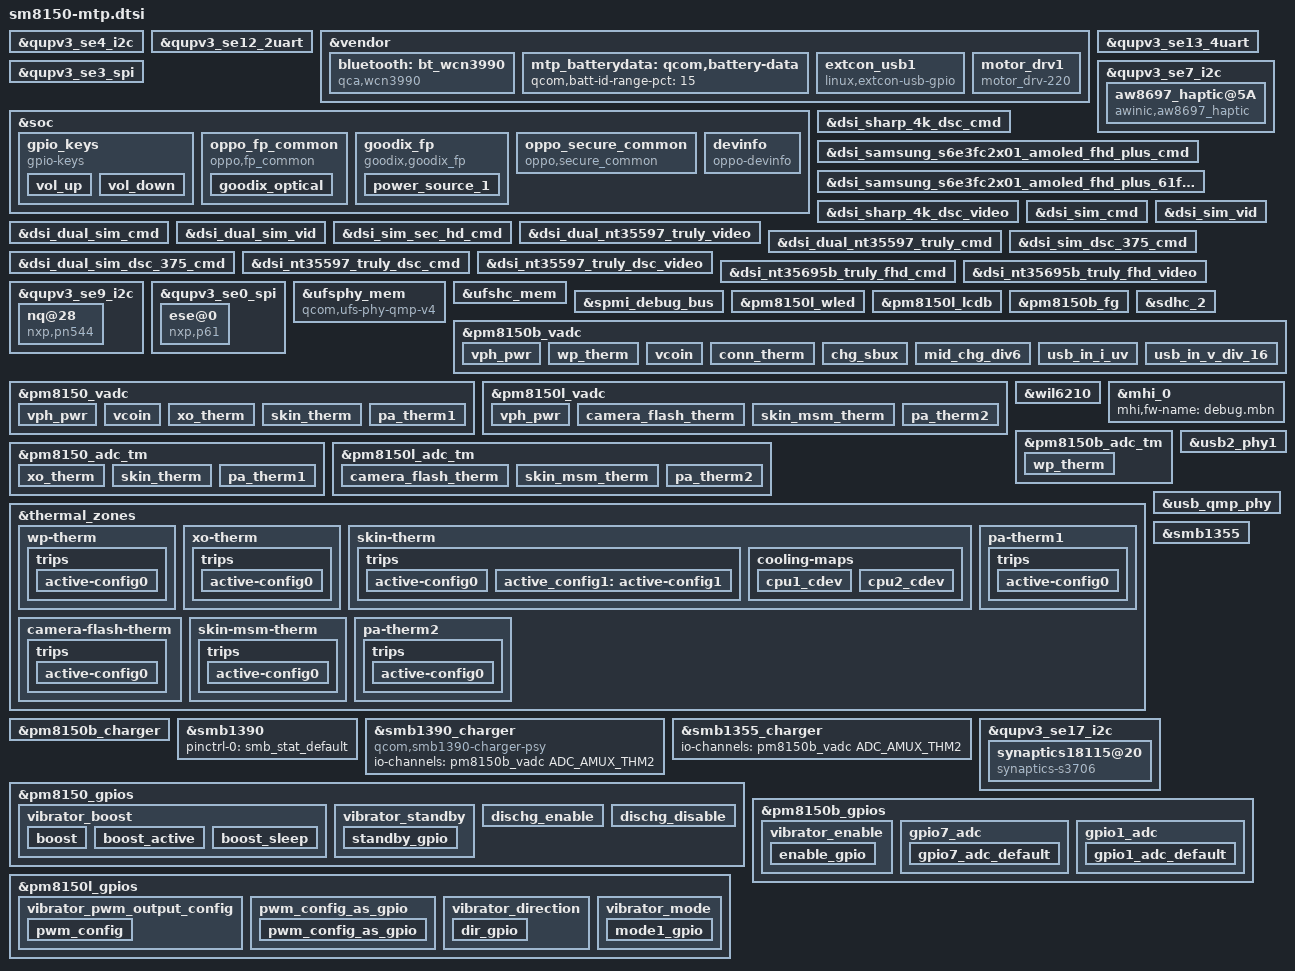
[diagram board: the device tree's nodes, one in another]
/* Copyright (c) 2017-2019, The Linux Foundation. All rights reserved.
 *
 * This program is free software; you can redistribute it and/or modify
 * it under the terms of the GNU General Public License version 2 and
 * only version 2 as published by the Free Software Foundation.
 *
 * This program is distributed in the hope that it will be useful,
 * but WITHOUT ANY WARRANTY; without even the implied warranty of
 * MERCHANTABILITY or FITNESS FOR A PARTICULAR PURPOSE.  See the
 * GNU General Public License for more details.
 */

#include <dt-bindings/gpio/gpio.h>
#include <dt-bindings/input/input.h>

#include "sm8150-pmic-overlay.dtsi"
#include "sm8150-sde-display.dtsi"
#include "sm8150-camera-sensor-mtp.dtsi"
#include "sm8150-thermal-overlay.dtsi"

&qupv3_se4_i2c {
#address-cells = <1>;
#size-cells = <0>;

#include "smb1390.dtsi"
#include "smb1355.dtsi"
};

&qupv3_se12_2uart {
	status = "ok";
};

&vendor {
	bluetooth: bt_wcn3990 {
		compatible = "qca,wcn3990";
		qca,bt-vdd-core-supply = <&pm8150_l7>;
		qca,bt-vdd-pa-supply = <&pm8150l_l2>;
		qca,bt-vdd-ldo-supply = <&pm8150l_l11>;

		qca,bt-vdd-core-voltage-level = <1800000 1800000>;
		qca,bt-vdd-pa-voltage-level = <1304000 1304000>;
		qca,bt-vdd-ldo-voltage-level = <3312000 3312000>;

		qca,bt-vdd-core-current-level = <0>; /* LPM/PFM */
		qca,bt-vdd-pa-current-level = <0>; /* LPM/PFM */
		qca,bt-vdd-ldo-current-level = <0>; /* LPM/PFM */
	};

	mtp_batterydata: qcom,battery-data {
		qcom,batt-id-range-pct = <15>;
		#include "fg-gen4-batterydata-alium-3600mah.dtsi"
	};

	extcon_usb1: extcon_usb1 {
		compatible = "linux,extcon-usb-gpio";
		//modify by cong.dai@psw.bsp.tp 2019/02/27, modified for motor
		//vbus-gpio = <&pm8150_gpios 10 GPIO_ACTIVE_HIGH>;
		/*#endif*/
                /*#ifdef VENDOR_EDIT*/
                //modify by Long.Liu 20190101, for fingerprint power gpio
		//id-gpio = <&tlmm 101 GPIO_ACTIVE_HIGH>;
                /*#endif*/
		//#ifdef VENDOR_EDIT /* tongfeng.Huang@BSP.CHG.Basic, 2018/01/08,  Add for charging chgID */
		//vbus-out-gpio = <&pm8150_gpios 9 GPIO_ACTIVE_HIGH>;
		//#endif

		pinctrl-names = "default";
		/*#ifdef VENDOR_EDIT*/
		//modify by Long.Liu 20190101, for fingerprint power gpio
		//pinctrl-0 = <&usb2_vbus_det_default
		//	     &usb2_id_det_default
		//	     &usb2_vbus_boost_default>;
		/*#endif*/

	};
};

&qupv3_se13_4uart {
	status = "ok";
};

&qupv3_se3_spi {
	status = "ok";
};

&qupv3_se4_i2c {
	status = "ok";
};


//#ifdef VENDOR_EDIT//Fanhong.Kong@ProDrv.CHG,add 2018/10/25 for vib aw8697
&qupv3_se7_i2c  {
    status = "okay";
	/* AWINIC AW8697 Haptic */
	aw8697_haptic@5A {
		compatible = "awinic,aw8697_haptic";
		reg = <0x5A>;
		reset-gpio = <&tlmm 116 0>;
		irq-gpio = <&tlmm 24 0>;
		status = "okay";

		pinctrl-names = "default";
		pinctrl-0 = <&aw_irq_gpio_default>;
	};
	/* AWINIC AW8697 Haptic End */
};
//#endif

&soc {
	gpio_keys {
		compatible = "gpio-keys";
		label = "gpio-keys";

		pinctrl-names = "default";
		/*ifdef VENDOR_EDIT*/
		//Added by wanghao@Bsp.Group.Tp for volkey,2018-11-01
		pinctrl-0 = <&key_vol_up_default &key_vol_down_default>;
		//#endif

		vol_up {
			label = "volume_up";
			gpios = <&pm8150_gpios 6 GPIO_ACTIVE_LOW>;
			linux,input-type = <1>;
			linux,code = <KEY_VOLUMEUP>;
			gpio-key,wakeup;
			debounce-interval = <15>;
			linux,can-disable;
		};

		/*ifdef VENDOR_EDIT*/
		//Added by Tong.han@Bsp.Group.Tp for device-info,2015-4-13
		vol_down {
			label = "volume_down";
			gpios = <&pm8150_gpios 7 GPIO_ACTIVE_LOW>;
			linux,input-type = <1>;
			linux,code = <KEY_VOLUMEDOWN>;
			gpio-key,wakeup;
			debounce-interval = <15>;
			linux,can-disable;
		};
		/*endif*/
	};
//#ifdef VENDOR_EDIT
//delete because this GPIO used for motor
//	qcom,qbt1000 {
//		compatible = "qcom,qbt1000";
//		clock-names = "core", "iface";
//		clock-frequency = <25000000>;
//		qcom,ipc-gpio = <&tlmm 118 0>;
//		pinctrl-names = "default";
//		pinctrl-0 = <&key_home_default>;
//		qcom,finger-detect-gpio = <&pm8150_gpios 1 0>;
//	};
//#endif

	/* #ifdef VENDOR_EDIT */
	/*Long.Liu@Bsp.Fingerprint.Basic 2018-11-27 add for fingerprint */
	oppo_fp_common {
	        compatible = "oppo,fp_common";
                oppo,fp_gpio = <130>;
                pinctrl-names = "default";
                pinctrl-0 = <&gpio_id2_default>;
                goodix_optical {
                        oppo,fp-id = <1>; /* fp id mapping table */
                        vendor-chip = <11>; /* please refer to the struct fp_vendor_t in oppo_fp_commmon.n */
                        eng-menu = "-1,-1"; /* represents SNR, inclination test item in engineer menu, and 0/1 means off/on */
                        chip-name = "G_OPTICAL_G2";  /* /proc/fp_id, will be displayed in engineer menu  */
		};
	};

	/*#ifdef VENDOR_EDIT Long.Liu@Bsp.Fingerprint.Basic 2018-11-27 add for goodix TEE */
	goodix_fp {
	        status = "ok";
	        compatible = "goodix,goodix_fp";
	        interrupt-parent = <&tlmm>;
                interrupts = <118 0>;
	        power-mode = <2> ; /*please refer to the struct fp_power_mode_t in oppo_fp_commmon.h ,0: power mode not set, 1: ldo power, 2: gpio power, 3: auto power */
	        goodix,gpio_irq = <&tlmm 118 0x1>;
	        goodix,gpio_reset = <&tlmm 131 0x0>;
	        goodix,goodix_pwr = <&tlmm 101 0x0>;
	        //ldo5-supply = <&pm660l_l5>;  // pm660l_l5 for goodix_fp
	        pinctrl-names = "default";
	        pinctrl-0 = <&gpio_goodix_irq_default>;
                power-num = <1>;
                power_source_1 {
                        power-mode = <2>;
                        power-name = "goodix,goodix_pwr";
                        delay-time = <0>;
                };
	};
	//#endif /*VENDOR_EDIT*/

	/* #ifdef VENDOR_EDIT */
	/* Long.Liu@BSP.Fingerprint.Secure 2018/12/29, add for oppo secure common */
	oppo_secure_common {
		compatible = "oppo,secure_common";
	};
	/* #endif VENDOR_EDIT */

	/*ifdef VENDOR_EDIT*/
	//Added by Tong.han@Bsp.Group.Tp for device-info,2015-4-13
	devinfo {
		compatible = "oppo-devinfo";
		Hw,sub_hwid_1 = <&pm8150b_gpios 8 0x00>;
		Hw,sub_hwid_2 = <&pm8150b_gpios 2 0x00>;
		pinctrl-names = "hw_sub1_active","hw_sub1_sleep","hw_sub2_active","hw_sub2_sleep";
		pinctrl-0 = <&hw_sub1_pullup>;
		pinctrl-1 = <&hw_sub1_pulldown>;
		pinctrl-2 = <&hw_sub2_pullup>;
		pinctrl-3 = <&hw_sub2_pulldown>;
	};
	/*endif*/
};

&dsi_sharp_4k_dsc_cmd {
	qcom,panel-supply-entries = <&dsi_panel_pwr_supply>;
	qcom,mdss-dsi-bl-pmic-control-type = "bl_ctrl_wled";
	qcom,mdss-dsi-bl-min-level = <1>;
	qcom,mdss-dsi-bl-max-level = <4095>;
	qcom,mdss-dsi-mode-sel-gpio-state = "dual_port";
	qcom,panel-mode-gpio = <&tlmm 7 0>;
	qcom,platform-te-gpio = <&tlmm 8 0>;
	qcom,platform-reset-gpio = <&tlmm 6 0>;
};

//#ifdef VENDOR_EDIT
/*
 * Gou shengjun@PSW.MM.Display.LCD.Stability, 2018/06/11,
 * modify for 18115 samsung amoled
 */
&dsi_samsung_s6e3fc2x01_amoled_fhd_plus_cmd {
	qcom,panel-supply-entries = <&dsi_panel_pwr_supply>;
	qcom,mdss-dsi-bl-pmic-control-type = "bl_ctrl_dcs";
	qcom,mdss-dsi-bl-min-level = <1>;
	qcom,mdss-dsi-bl-max-level = <1023>;
	qcom,platform-te-gpio = <&tlmm 8 0>;
	qcom,platform-reset-gpio = <&tlmm 6 0>;
};

&dsi_samsung_s6e3fc2x01_amoled_fhd_plus_61fps_cmd {
	qcom,panel-supply-entries = <&dsi_panel_pwr_supply>;
	qcom,mdss-dsi-bl-pmic-control-type = "bl_ctrl_dcs";
	qcom,mdss-dsi-bl-min-level = <1>;
	qcom,mdss-dsi-bl-max-level = <1023>;
	qcom,platform-te-gpio = <&tlmm 8 0>;
	qcom,platform-reset-gpio = <&tlmm 6 0>;
};
//#endif /*VENDOR_EDIT*/

&dsi_sharp_4k_dsc_video {
	qcom,panel-supply-entries = <&dsi_panel_pwr_supply>;
	qcom,mdss-dsi-bl-pmic-control-type = "bl_ctrl_wled";
	qcom,mdss-dsi-bl-min-level = <1>;
	qcom,mdss-dsi-bl-max-level = <4095>;
	qcom,mdss-dsi-mode-sel-gpio-state = "dual_port";
	qcom,panel-mode-gpio = <&tlmm 7 0>;
	qcom,platform-te-gpio = <&tlmm 8 0>;
	qcom,platform-reset-gpio = <&tlmm 6 0>;
};

&dsi_sim_cmd {
	qcom,panel-supply-entries = <&dsi_panel_pwr_supply>;
	qcom,mdss-dsi-bl-pmic-control-type = "bl_ctrl_dcs";
	qcom,platform-reset-gpio = <&tlmm 6 0>;
};

&dsi_sim_vid {
	qcom,panel-supply-entries = <&dsi_panel_pwr_supply>;
	qcom,mdss-dsi-bl-pmic-control-type = "bl_ctrl_dcs";
	qcom,platform-reset-gpio = <&tlmm 6 0>;
};

&dsi_dual_sim_cmd {
	qcom,panel-supply-entries = <&dsi_panel_pwr_supply>;
	qcom,mdss-dsi-bl-pmic-control-type = "bl_ctrl_dcs";
	qcom,platform-reset-gpio = <&tlmm 6 0>;
};

&dsi_dual_sim_vid {
	qcom,panel-supply-entries = <&dsi_panel_pwr_supply>;
	qcom,mdss-dsi-bl-pmic-control-type = "bl_ctrl_dcs";
	qcom,platform-reset-gpio = <&tlmm 6 0>;
};

&dsi_sim_sec_hd_cmd {
	qcom,panel-supply-entries = <&dsi_panel_pwr_supply>;
	qcom,panel-sec-supply-entries = <&dsi_panel_pwr_supply_vdd_no_labibb>;
	qcom,mdss-dsi-bl-pmic-control-type = "bl_ctrl_wled";
	qcom,mdss-dsi-bl-min-level = <1>;
	qcom,mdss-dsi-bl-max-level = <4095>;
	qcom,mdss-dsi-mode-sel-gpio-state = "single_port";
	qcom,panel-mode-gpio = <&tlmm 7 0>;
	qcom,platform-reset-gpio = <&tlmm 6 0>;
	qcom,panel-sec-mode-gpio = <&tlmm 77 0>;
	qcom,platform-sec-reset-gpio = <&tlmm 66 0>;
};

&dsi_dual_nt35597_truly_video {
	qcom,panel-supply-entries = <&dsi_panel_pwr_supply>;
	qcom,mdss-dsi-bl-pmic-control-type = "bl_ctrl_wled";
	qcom,mdss-dsi-bl-min-level = <1>;
	qcom,mdss-dsi-bl-max-level = <4095>;
	qcom,mdss-dsi-mode-sel-gpio-state = "dual_port";
	qcom,panel-mode-gpio = <&tlmm 7 0>;
	qcom,platform-te-gpio = <&tlmm 8 0>;
	qcom,platform-reset-gpio = <&tlmm 6 0>;
};

&dsi_dual_nt35597_truly_cmd {
	qcom,panel-supply-entries = <&dsi_panel_pwr_supply>;
	qcom,mdss-dsi-bl-pmic-control-type = "bl_ctrl_wled";
	qcom,mdss-dsi-bl-min-level = <1>;
	qcom,mdss-dsi-bl-max-level = <4095>;
	qcom,mdss-dsi-mode-sel-gpio-state = "dual_port";
	qcom,panel-mode-gpio = <&tlmm 7 0>;
	qcom,platform-te-gpio = <&tlmm 8 0>;
	qcom,platform-reset-gpio = <&tlmm 6 0>;
};

&dsi_sim_dsc_375_cmd {
	qcom,panel-supply-entries = <&dsi_panel_pwr_supply>;
	qcom,mdss-dsi-bl-pmic-control-type = "bl_ctrl_dcs";
	qcom,platform-reset-gpio = <&tlmm 6 0>;
};

&dsi_dual_sim_dsc_375_cmd {
	qcom,panel-supply-entries = <&dsi_panel_pwr_supply>;
	qcom,mdss-dsi-bl-pmic-control-type = "bl_ctrl_dcs";
	qcom,platform-reset-gpio = <&tlmm 6 0>;
};

&dsi_nt35597_truly_dsc_cmd {
	qcom,panel-supply-entries = <&dsi_panel_pwr_supply>;
	qcom,mdss-dsi-bl-pmic-control-type = "bl_ctrl_wled";
	qcom,mdss-dsi-bl-min-level = <1>;
	qcom,mdss-dsi-bl-max-level = <4095>;
	qcom,mdss-dsi-mode-sel-gpio-state = "single_port";
	qcom,panel-mode-gpio = <&tlmm 7 0>;
	qcom,platform-te-gpio = <&tlmm 8 0>;
	qcom,platform-reset-gpio = <&tlmm 6 0>;
};

&dsi_nt35597_truly_dsc_video {
	qcom,panel-supply-entries = <&dsi_panel_pwr_supply>;
	qcom,mdss-dsi-bl-pmic-control-type = "bl_ctrl_wled";
	qcom,mdss-dsi-bl-min-level = <1>;
	qcom,mdss-dsi-bl-max-level = <4095>;
	qcom,mdss-dsi-mode-sel-gpio-state = "single_port";
	qcom,panel-mode-gpio = <&tlmm 7 0>;
	qcom,platform-te-gpio = <&tlmm 8 0>;
	qcom,platform-reset-gpio = <&tlmm 6 0>;
};

&dsi_nt35695b_truly_fhd_cmd {
	qcom,panel-supply-entries = <&dsi_panel_pwr_supply>;
	qcom,mdss-dsi-bl-pmic-control-type = "bl_ctrl_wled";
	qcom,mdss-dsi-bl-min-level = <1>;
	qcom,mdss-dsi-bl-max-level = <4095>;
	qcom,mdss-dsi-mode-sel-gpio-state = "single_port";
	qcom,panel-mode-gpio = <&tlmm 7 0>;
	qcom,platform-te-gpio = <&tlmm 8 0>;
	qcom,platform-reset-gpio = <&tlmm 6 0>;
};

&dsi_nt35695b_truly_fhd_video {
	qcom,panel-supply-entries = <&dsi_panel_pwr_supply>;
	qcom,mdss-dsi-bl-pmic-control-type = "bl_ctrl_wled";
	qcom,mdss-dsi-bl-min-level = <1>;
	qcom,mdss-dsi-bl-max-level = <4095>;
	qcom,mdss-dsi-mode-sel-gpio-state = "single_port";
	qcom,panel-mode-gpio = <&tlmm 7 0>;
	qcom,platform-te-gpio = <&tlmm 8 0>;
	qcom,platform-reset-gpio = <&tlmm 6 0>;
};

//#ifndef VENDOR_EDIT
//Weiwei.Deng@CN.NFC.Basic.Hardware.1746553, 2018/12/20,
//Modify for dtsi for NXP NFC
/*&qupv3_se9_i2c {
	status = "ok";

	#address-cells = <1>;
	#size-cells = <0>;

	nq@28 {
		compatible = "qcom,nq-nci";
		reg = <0x28>;
		qcom,nq-irq = <&tlmm 47 0x00>;
		qcom,nq-ven = <&tlmm 41 0x00>;
		qcom,nq-firm = <&tlmm 48 0x00>;
		qcom,nq-clkreq = <&tlmm 113 0x00>;
		qcom,nq-esepwr = <&tlmm 42 0x00>;
		interrupt-parent = <&tlmm>;
		interrupts = <47 0>;
		interrupt-names = "nfc_irq";
		pinctrl-names = "nfc_active", "nfc_suspend";
		pinctrl-0 = <&nfc_int_active &nfc_enable_active
					&nfc_clk_req_active>;
		pinctrl-1 = <&nfc_int_suspend &nfc_enable_suspend
					&nfc_clk_req_suspend>;
	};
};
*/
//#else /* VENDOR_EDIT */
&qupv3_se9_i2c {
	status = "ok";
	nq@28 {
		compatible = "nxp,pn544";
		reg = <0x28>;
		nxp,pn544-irq = <&tlmm 47 0x00>;
		nxp,pn544-ven = <&tlmm 41 0x00>;
		nxp,pn544-fw-dwnld = <&tlmm 48 0x00>;
		nxp,pn544-clk-gpio = <&tlmm 113 0x00>;
		nxp,pn544-ese-pwr = <&tlmm 49 0x00>;
		interrupt-parent = <&tlmm>;
		qcom,clk-src = "BBCLK3";
		interrupts = <47 0>;
		interrupt-names = "nfc_irq";
		pinctrl-names = "nfc_active", "nfc_suspend";
		pinctrl-0 = <&nfc_int_active &nfc_enable_active
					&nfc_clk_req_active>;
		pinctrl-1 = <&nfc_int_suspend &nfc_enable_suspend
					&nfc_clk_req_suspend>;
	};
};

&qupv3_se0_spi {
    status = "ok";

    ese@0 {
        compatible = "nxp,p61";
        reg = <0>;
        spi-max-frequency = <8000000>;
    };
};
//#endif /* VENDOR_EDIT */
&ufsphy_mem {
	compatible = "qcom,ufs-phy-qmp-v4";

	vdda-phy-supply = <&pm8150_l5>;
	vdda-phy-always-on;
	vdda-pll-supply = <&pm8150l_l3>;
	vdda-phy-max-microamp = <90200>;
	vdda-pll-max-microamp = <19000>;

	status = "ok";
};

&ufshc_mem {
	vdd-hba-supply = <&ufs_phy_gdsc>;
	vdd-hba-fixed-regulator;
	vcc-supply = <&pm8150_l10>;
	vcc-voltage-level = <2504000 2950000>;
	vcc-low-voltage-sup;
	vccq-supply = <&pm8150_l9>;
	vccq2-supply = <&pm8150_s4>;
	vcc-max-microamp = <750000>;
	vccq-max-microamp = <700000>;
	vccq2-max-microamp = <750000>;

	qcom,vddp-ref-clk-supply = <&pm8150_l9>;
	qcom,vddp-ref-clk-max-microamp = <100>;

	status = "ok";
};

&spmi_debug_bus {
	status = "ok";
};

&pm8150l_wled {
	qcom,string-cfg= <7>;
	qcom,leds-per-string = <6>;
	status = "ok";
};

&pm8150l_lcdb {
	status = "ok";
};

&pm8150b_fg {
	qcom,battery-data = <&mtp_batterydata>;
	qcom,hold-soc-while-full;
	qcom,linearize-soc;
	qcom,five-pin-battery;
	qcom,cl-wt-enable;
	/* ESR fast calibration */
	qcom,fg-esr-timer-chg-fast = <0 7>;
	qcom,fg-esr-timer-dischg-fast = <0 7>;
	qcom,fg-esr-timer-chg-slow = <0 96>;
	qcom,fg-esr-timer-dischg-slow = <0 96>;
	qcom,fg-esr-cal-soc-thresh = <26 230>;
	qcom,fg-esr-cal-temp-thresh = <10 40>;
};

&sdhc_2 {
	vdd-supply = <&pm8150l_l9>;
	qcom,vdd-voltage-level = <2950000 2960000>;
	qcom,vdd-current-level = <200 800000>;

	vdd-io-supply = <&pm8150l_l6>;
	qcom,vdd-io-voltage-level = <1808000 2960000>;
	qcom,vdd-io-current-level = <200 22000>;

	pinctrl-names = "active", "sleep";
	pinctrl-0 = <&sdc2_clk_on  &sdc2_cmd_on &sdc2_data_on &storage_cd>;
	pinctrl-1 = <&sdc2_clk_off &sdc2_cmd_off &sdc2_data_off &storage_cd>;
//#ifndef VENDOR_EDIT
//yh@PSW.BSP.Storage.Sdcard, 2018-11-012, Add for SD card detect
	//cd-gpios = <&tlmm 96 GPIO_ACTIVE_LOW>;
//#else
	cd-gpios = <&tlmm 96 GPIO_ACTIVE_HIGH>;
//#endif

	status = "ok";
};

&pm8150b_vadc {
	vph_pwr {
		reg = <ADC_VPH_PWR>;
		label = "vph_pwr";
		qcom,pre-scaling = <1 3>;
	};

	wp_therm {
		reg = <ADC_AMUX_THM1_PU2>;
		label = "wp_therm";
		qcom,ratiometric;
		qcom,hw-settle-time = <200>;
		qcom,pre-scaling = <1 1>;
	};

	vcoin {
		reg = <ADC_VCOIN>;
		label = "vcoin";
		qcom,pre-scaling = <1 3>;
	};

	conn_therm {
		reg = <ADC_AMUX_THM3_PU2>;
		label = "conn_therm";
		qcom,ratiometric;
		qcom,hw-settle-time = <200>;
		qcom,pre-scaling = <1 1>;
	};

	chg_sbux {
		reg = <ADC_SBUx>;
		label = "chg_sbux";
		qcom,pre-scaling = <1 3>;
	};

	mid_chg_div6 {
		reg = <ADC_MID_CHG_DIV6>;
		label = "chg_mid";
		qcom,pre-scaling = <1 6>;
	};

	usb_in_i_uv {
		reg = <ADC_USB_IN_I>;
		label = "usb_in_i_uv";
		qcom,pre-scaling = <1 1>;
	};

	usb_in_v_div_16 {
		reg = <ADC_USB_IN_V_16>;
		label = "usb_in_v_div_16";
		qcom,pre-scaling = <1 16>;
	};
};

&pm8150_vadc {
	vph_pwr {
		reg = <ADC_VPH_PWR>;
		label = "vph_pwr";
		qcom,pre-scaling = <1 3>;
	};

	vcoin {
		reg = <ADC_VCOIN>;
		label = "vcoin";
		qcom,pre-scaling = <1 3>;
	};

	xo_therm {
		reg = <ADC_XO_THERM_PU2>;
		label = "xo_therm";
		qcom,ratiometric;
		qcom,hw-settle-time = <200>;
		qcom,pre-scaling = <1 1>;
	};

	skin_therm {
		reg = <ADC_AMUX_THM1_PU2>;
		label = "skin_therm";
		qcom,ratiometric;
		qcom,hw-settle-time = <200>;
		qcom,pre-scaling = <1 1>;
	};

	pa_therm1 {
		reg = <ADC_AMUX_THM2_PU2>;
		label = "pa_therm1";
		qcom,ratiometric;
		qcom,hw-settle-time = <200>;
		qcom,pre-scaling = <1 1>;
	};
};

&pm8150l_vadc {
	vph_pwr {
		reg = <ADC_VPH_PWR>;
		label = "vph_pwr";
		qcom,pre-scaling = <1 3>;
	};

	camera_flash_therm {
		reg = <ADC_AMUX_THM1_PU2>;
		label = "camera_flash_therm";
		qcom,ratiometric;
		qcom,hw-settle-time = <200>;
		qcom,pre-scaling = <1 1>;
	};

	skin_msm_therm {
		reg = <ADC_AMUX_THM2_PU2>;
		label = "skin_msm_therm";
		qcom,ratiometric;
		qcom,hw-settle-time = <200>;
		qcom,pre-scaling = <1 1>;
	};

	pa_therm2 {
		reg = <ADC_AMUX_THM3_PU2>;
		label = "pa_therm2";
		qcom,ratiometric;
		qcom,hw-settle-time = <200>;
		qcom,pre-scaling = <1 1>;
	};
};

&wil6210 {
	status = "ok";
};

&mhi_0 {
	mhi,fw-name = "debug.mbn";
};

&pm8150b_adc_tm {
	wp_therm {
		reg = <ADC_AMUX_THM1_PU2>;
		qcom,ratiometric;
		qcom,hw-settle-time = <200>;
	};
};

&pm8150_adc_tm {
	xo_therm {
		reg = <ADC_XO_THERM_PU2>;
		qcom,ratiometric;
		qcom,hw-settle-time = <200>;
	};

	skin_therm {
		reg = <ADC_AMUX_THM1_PU2>;
		qcom,ratiometric;
		qcom,hw-settle-time = <200>;
	};

	pa_therm1 {
		reg = <ADC_AMUX_THM2_PU2>;
		qcom,ratiometric;
		qcom,hw-settle-time = <200>;
	};
};

&pm8150l_adc_tm {
	camera_flash_therm {
		reg = <ADC_AMUX_THM1_PU2>;
		qcom,ratiometric;
		qcom,hw-settle-time = <200>;
	};

	skin_msm_therm {
		reg = <ADC_AMUX_THM2_PU2>;
		qcom,ratiometric;
		qcom,hw-settle-time = <200>;
	};

	pa_therm2 {
		reg = <ADC_AMUX_THM3_PU2>;
		qcom,ratiometric;
		qcom,hw-settle-time = <200>;
	};
};

&thermal_zones {
	wp-therm {
		polling-delay-passive = <0>;
		polling-delay = <0>;
		thermal-governor = "user_space";
		thermal-sensors = <&pm8150b_adc_tm ADC_AMUX_THM1_PU2>;
		wake-capable-sensor;
		trips {
			active-config0 {
				temperature = <125000>;
				hysteresis = <1000>;
				type = "passive";
			};
		};
	};

	xo-therm {
		polling-delay-passive = <0>;
		polling-delay = <0>;
		thermal-governor = "user_space";
		thermal-sensors = <&pm8150_adc_tm ADC_XO_THERM_PU2>;
		wake-capable-sensor;
		trips {
			active-config0 {
				temperature = <125000>;
				hysteresis = <1000>;
				type = "passive";
			};
		};
	};

	skin-therm {
		polling-delay-passive = <50>;
		polling-delay = <200>;
		thermal-governor = "step_wise";
		thermal-sensors = <&pm8150_adc_tm ADC_AMUX_THM1_PU2>;
		/* #ifdef VENDOR_EDIT */
		temp-track;
		/* #endif */
		wake-capable-sensor;
		trips {
			active-config0 {
				temperature = <125000>;
				hysteresis = <1000>;
				type = "passive";
			};
			active_config1: active-config1 {
				temperature = <45000>;
				hysteresis = <1000>;
				type = "passive";
			};
		};
		cooling-maps {
			cpu1_cdev {
				trip = <&active_config1>;
				cooling-device = <&CPU4 THERMAL_NO_LIMIT 12>;
			};
			cpu2_cdev {
				trip = <&active_config1>;
				cooling-device = <&CPU7 THERMAL_NO_LIMIT 15>;
			};
		};
	};

	pa-therm1 {
		polling-delay-passive = <0>;
		polling-delay = <0>;
		thermal-governor = "user_space";
		thermal-sensors = <&pm8150_adc_tm ADC_AMUX_THM2_PU2>;
		wake-capable-sensor;
		trips {
			active-config0 {
				temperature = <125000>;
				hysteresis = <1000>;
				type = "passive";
			};
		};
	};

	camera-flash-therm {
		polling-delay-passive = <0>;
		polling-delay = <0>;
		thermal-governor = "user_space";
		thermal-sensors = <&pm8150l_adc_tm ADC_AMUX_THM1_PU2>;
		wake-capable-sensor;
		trips {
			active-config0 {
				temperature = <125000>;
				hysteresis = <1000>;
				type = "passive";
			};
		};
	};

	skin-msm-therm {
		polling-delay-passive = <0>;
		polling-delay = <0>;
		thermal-governor = "user_space";
		thermal-sensors = <&pm8150l_adc_tm ADC_AMUX_THM2_PU2>;
		wake-capable-sensor;
		trips {
			active-config0 {
				temperature = <125000>;
				hysteresis = <1000>;
				type = "passive";
			};
		};
	};

	pa-therm2 {
		polling-delay-passive = <0>;
		polling-delay = <0>;
		thermal-governor = "user_space";
		thermal-sensors = <&pm8150l_adc_tm ADC_AMUX_THM3_PU2>;
		wake-capable-sensor;
		trips {
			active-config0 {
				temperature = <125000>;
				hysteresis = <1000>;
				type = "passive";
			};
		};
	};
};

&pm8150b_charger {
	qcom,sec-charger-config = <3>;
	qcom,auto-recharge-soc = <98>;
	io-channels = <&pm8150b_vadc ADC_MID_CHG_DIV6>,
		      <&pm8150b_vadc ADC_USB_IN_I>,
		      <&pm8150b_vadc ADC_SBUx>,
		      <&pm8150b_vadc ADC_VPH_PWR>,
//#ifdef VENDOR_EDIT /* tongfeng.Huang@BSP.CHG.Basic, 2016/12/26,  Add for charging chgID */
		      <&pm8150b_vadc ADC_CHG_TEMP>,
			  <&pm8150b_vadc ADC_GPIO3>,
			  <&pm8150b_vadc ADC_AMUX_THM4_PU2>;
//#else
		      //<&pm8150b_vadc ADC_CHG_TEMP>;
//#endif
	io-channel-names = "mid_voltage",
			   "usb_in_current",
			   "sbux_res",
			   "vph_voltage",
//#ifdef VENDOR_EDIT /* tongfeng.Huang@BSP.CHG.Basic, 2016/12/26,  Add for charging chgID */
			   "chg_temp",
			   "chgID_voltage_adc",
			   "usb_temp_adc";
//#else
				///"chg_temp";
//#endif
	qcom,battery-data = <&mtp_batterydata>;
//#ifdef VENDOR_EDIT  /* zhangkun@BSP.CHG.Basic, 2019/02/22, Add for disable water detect*/
	qcom,lpd-disable;
//#endif
	qcom,step-charging-enable;
	qcom,sw-jeita-enable;
	qcom,wd-bark-time-secs = <16>;
	qcom,suspend-input-on-debug-batt;
};

&smb1390 {
	pinctrl-names = "default";
	pinctrl-0 = <&smb_stat_default>;
	status = "ok";
};

&smb1390_charger {
	/delete-property/ compatible;
	compatible = "qcom,smb1390-charger-psy";
	io-channels = <&pm8150b_vadc ADC_AMUX_THM2>;
	io-channel-names = "cp_die_temp";
	status = "ok";
};

/*#ifdef VENDOR_EDIT*/
//modify by Long.Liu 20190101, for fingerprint power gpio
/*
&usb1 {
	extcon = <&extcon_usb1>;
	status = "ok";
};
*/
/*#endif*/

&usb2_phy1 {
	status = "ok";
};

&usb_qmp_phy {
	status = "ok";
};

&smb1355 {
	status = "ok";
};

&smb1355_charger {
	io-channels = <&pm8150b_vadc ADC_AMUX_THM2>;
	io-channel-names = "charger_temp";
	status = "ok";
};
//#ifdef VENDOR_EDIT
//cong.dai@BSP.group 2018-11-02 add for cs press & touchpanel
&qupv3_se17_i2c  {
	status = "okay";
	synaptics18115@20 {
		compatible = "synaptics-s3706";
		reg = <0x20>;
		chip-name = "S3706";

		/* Interrupt && Irq-gpio */
		interrupt-parent = <&tlmm>;
		interrupts = <122 0x00>;

		/* Power Config */
		vdd_2v8-supply = <&touchpanel_vdd>;
		vcc_1v8-supply = <&pm8150_l14>;

		/* Other HW Resource */
		irq-gpio = <&tlmm 122 0x2008>;
		reset-gpio = <&tlmm 54 0x1>;
		pinctrl-names = "default";
		pinctrl-0 = <&ts_int_active &ts_reset_active>;

		touchpanel,max-num-support = <10>;
		touchpanel,tx-rx-num = <16 34>;
		touchpanel,panel-coords = <1080 2340>;
		touchpanel,display-coords = <1080 2340>;
		touchpanel,touchmajor-limit = <0 54>;

		/* SW Support Feature Control */
		black_gesture_support;
		fw_edge_limit_support;
		fw_corner_limit_support;
		charger_pump_support;
		game_switch_support;
		face_detect_support;
		smart_gesture_support;
		pressure_report_support;
		fw_update_app_support;
		fingerprint_underscreen_support;
		report_point_first_support;
		rt155_fdreplace_rt59_support;

		touchpanel,button-type = <4>;
		touchpanel.button-TRx = <0 0>;
	};
};
//#endif
//#ifdef VENDOR_EDIT
//add and modify motor config
&pm8150_gpios {
	vibrator_boost{
		boost: boost {
			pins = "gpio1";
			function = "normal";
			input-disable; //pull down
			power-source = <0>; // must be 0
			output-high; //digital output, no invert
			qcom,drive-strength = <3>;//0.15
		};

		boost_active:boost_active {
			pins = "gpio1";
			function = "normal";
			input-disable; //pull down
			power-source = <0>; // must be 0
			output-high; //digital output, no invert
			qcom,drive-strength = <3>;//0.15
		};

		boost_sleep:boost_sleep {
			pins = "gpio1";
			function = "normal";
			input-disable; //pull down
			power-source = <0>; // must be 0
			output-low; //digital output, no invert
			qcom,drive-strength = <3>;//0.15
		};
	};

	vibrator_standby{
		standby_gpio: standby_gpio {
			pins = "gpio10";
			function = "normal";//
			bias-disable; //No Pull
			power-source = <1>;//VIN1
			output-low; //digital output, no invert
			qcom,drive-strength = <3>; //LOW strength
			drive-push-pull;//CMOS
		};
	};
};

&pm8150l_gpios {
	//pwm mode
	vibrator_pwm_output_config{
		pwm_config: pwm_config {
			pins = "gpio10";//GPIO 10
			function = "func1";//Special Function 1,pwm
			bias-disable; //No Pull
			power-source = <1>;//VIN1
			output-low; //digital output, no invert
			qcom,drive-strength = <3>; //LOW strength
			drive-push-pull;//CMOS
		};
	};
	//gpio mode for stspin220
	pwm_config_as_gpio{
		pwm_config_as_gpio: pwm_config_as_gpio {
			pins = "gpio10";//GPIO 10
			function = "normal";//
			bias-disable; //No Pull
			power-source = <1>;//VIN1
			output-low; //digital output, no invert
			qcom,drive-strength = <3>; //LOW strength
			drive-push-pull;//CMOS
		};
	};

	vibrator_direction{
		dir_gpio: dir_gpio {
			pins = "gpio11";//GPIO 10
			function = "normal";//
			bias-disable; //No Pull
			power-source = <1>;//VIN1
			output-low; //digital output, no invert
			qcom,drive-strength = <3>; //LOW strength
			drive-push-pull;//CMOS
		};
	};
	vibrator_mode{
		mode1_gpio: mode1_gpio {
			pins = "gpio8";//GPIO 10
			function = "normal";//
			bias-disable; //No Pull
			power-source = <1>;//VIN1
			output-low; //digital output, no invert
			qcom,drive-strength = <3>; //LOW strength
			drive-push-pull;//CMOS
		};
	};
};

&pm8150b_gpios{
	vibrator_enable{
		enable_gpio: enable_gpio {
			pins = "gpio5";//GPIO 10
			function = "normal";//
			bias-disable; //No Pull
			power-source = <1>;//VIN1
			output-low; //digital output, no invert
			qcom,drive-strength = <3>; //LOW strength
			drive-push-pull;//CMOS
		};
	};
};
&vendor  {
	motor_drv1: motor_drv1 {
		compatible = "motor_drv-220";
		pinctrl-names = "boost","pwm_config","pwm_config_as_gpio","enable_gpio","dir_gpio","standby_gpio","mode1_gpio","motor_active","motor_sleep";
		pinctrl-0 = <&boost>;
		pinctrl-1 = <&pwm_config>;
		pinctrl-2 = <&pwm_config_as_gpio>;
		pinctrl-3 = <&enable_gpio>;
		pinctrl-4 = <&dir_gpio>;
		pinctrl-5 = <&standby_gpio>;
		pinctrl-6 = <&mode1_gpio>;
		pinctrl-7 = <&boost_active>;
		pinctrl-8 = <&boost_sleep>;

		pwms = <&pm8150l_pwm 1 1000000>;
		boost-gpio = <&pm8150_gpios 1 GPIO_ACTIVE_HIGH>;
		standby-gpio = <&pm8150_gpios 10 0>;
		dir-gpio = <&pm8150l_gpios 11 0>;
		enable-gpio =  <&pm8150b_gpios 5 0>;
		//step-gpio = <&pm8150l_gpios 10 0>;
		mode1-gpio = <&pm8150l_gpios 8 0>;
		ratio-a = <24>;
		ratio-b = <1840>;//18.40
		ratio-c = <20>;
		ratio-d = <32>;

	};
};
//#endif//VENDOR_EDIT

//#ifdef VENDOR_EDIT
/* tongfeng.Huang@BSP.CHG.Basic, 2018/11/02,  Add for charging chargerid adc*/
&pm8150b_gpios {
    gpio7_adc {
        gpio7_adc_default: gpio7_adc_default {
        pins = "gpio7"; /* GPIO 7 */
        function = "normal"; /* normal */
        bias-high-impedance; /* DISABLE GPIO7 for ADC*/
        };
    };    
	gpio1_adc {
        gpio1_adc_default: gpio1_adc_default {
        pins = "gpio1"; /* GPIO 1 */
        function = "normal"; /* normal */
        bias-high-impedance; /* DISABLE GPIO1 for ADC*/
        };
    };
};
&pm8150_gpios {
	dischg_enable: dischg_enable {
		pins = "gpio9"; /* GPIO 9 */
		function = "normal"; /* normal */
		bias-disable; //No Pull
		power-source = <0>;//VIN0 3.3
		output-high; //digital output, no invert
		qcom,drive-strength = <3>; //LOW strength
		//drive-push-pull;//CMOS
	};

	dischg_disable: dischg_disable {
		pins = "gpio9"; /* GPIO 9 */
		function = "normal"; /* normal */
		bias-disable; //No Pull
		power-source = <0>;//VIN0 3.3
		output-low; //digital output, no invert
		qcom,drive-strength = <3>; //LOW strength
		//drive-push-pull;//CMOS
	};
};
//#endif
